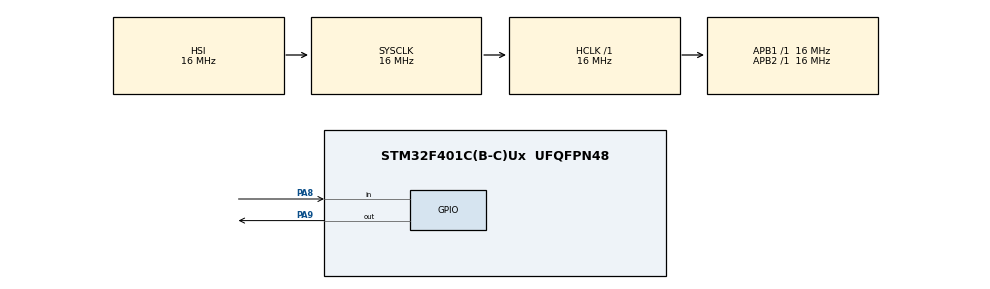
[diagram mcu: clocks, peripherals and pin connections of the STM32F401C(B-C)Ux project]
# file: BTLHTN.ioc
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FREERTOS.BinarySemaphores01=myBinarySem01,Dynamic,NULL
FREERTOS.Tasks01=defaultTask,0,128,StartDefaultTask,Default,NULL,Dynamic,NULL,NULL
Mcu.Family=STM32F4
Mcu.Name=STM32F401C(B-C)Ux
Mcu.Package=UFQFPN48
NVIC.PriorityGroup=NVIC_PRIORITYGROUP_4
NVIC.TIM1_UP_TIM10_IRQn=true\:15\:0\:false\:false\:true\:false\:false\:true
NVIC.TimeBase=TIM1_UP_TIM10_IRQn
NVIC.TimeBaseIP=TIM1
PA8.Signal=GPIO_Input
PA9.Signal=GPIO_Output
ProjectManager.HeapSize=0x200
ProjectManager.StackSize=0x400
ProjectManager.TargetToolchain=MDK-ARM V5.32
RCC.AHBFreq_Value=16000000
RCC.APB1Freq_Value=16000000
RCC.APB1TimFreq_Value=16000000
RCC.APB2Freq_Value=16000000
RCC.APB2TimFreq_Value=16000000
RCC.CortexFreq_Value=16000000
RCC.HCLKFreq_Value=16000000
RCC.HSE_VALUE=25000000
RCC.HSI_VALUE=16000000
RCC.LSE_VALUE=32768
RCC.SYSCLKFreq_VALUE=16000000
RCC.VCOOutputFreq_Value=192000000
TIM2.Period=65535
VP_FREERTOS_VS_CMSIS_V1.Mode=CMSIS_V1
VP_SYS_VS_tim1.Mode=TIM1
VP_TIM2_VS_ClockSourceINT.Mode=Internal
board=custom

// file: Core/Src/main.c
/* USER CODE BEGIN Header */
/**
  ******************************************************************************
  * @file           : main.c
  * @brief          : Main program body
  ******************************************************************************
  * @attention
  *
  * <h2><center>&copy; Copyright (c) 2022 STMicroelectronics.
  * All rights reserved.</center></h2>
  *
  * This software component is licensed by ST under Ultimate Liberty license
  * SLA0044, the "License"; You may not use this file except in compliance with
  * the License. You may obtain a copy of the License at:
  *                             www.st.com/SLA0044
  *
  ******************************************************************************
  */
/* USER CODE END Header */
#include "main.h"
#include "cmsis_os.h"

TIM_HandleTypeDef htim2;

osThreadId defaultTaskHandle;
osSemaphoreId myBinarySem01Handle;

void SystemClock_Config(void);
static void MX_GPIO_Init(void);
static void MX_TIM2_Init(void);
void StartDefaultTask(void const * argument);

int main(void)
{

  /* MCU Configuration--------------------------------------------------------*/

  /* Reset of all peripherals, Initializes the Flash interface and the Systick. */
  HAL_Init();

  /* Configure the system clock */
  SystemClock_Config();

  /* Initialize all configured peripherals */
  MX_GPIO_Init();
  MX_TIM2_Init();

  /* Create the semaphores(s) */
  /* definition and creation of myBinarySem01 */
  osSemaphoreDef(myBinarySem01);
  myBinarySem01Handle = osSemaphoreCreate(osSemaphore(myBinarySem01), 1);

  /* Create the thread(s) */
  /* definition and creation of defaultTask */
  osThreadDef(defaultTask, StartDefaultTask, osPriorityNormal, 0, 128);
  defaultTaskHandle = osThreadCreate(osThread(defaultTask), NULL);

  /* Start scheduler */
  osKernelStart();

  /* We should never get here as control is now taken by the scheduler */
  /* Infinite loop */
  while (1)
  {

  }
}

void SystemClock_Config(void)
{
  RCC_OscInitTypeDef RCC_OscInitStruct = {0};
  RCC_ClkInitTypeDef RCC_ClkInitStruct = {0};

  /** Configure the main internal regulator output voltage
  */
  __HAL_RCC_PWR_CLK_ENABLE();
  __HAL_PWR_VOLTAGESCALING_CONFIG(PWR_REGULATOR_VOLTAGE_SCALE2);
  /** Initializes the RCC Oscillators according to the specified parameters
  * in the RCC_OscInitTypeDef structure.
  */
  RCC_OscInitStruct.OscillatorType = RCC_OSCILLATORTYPE_HSI;
  RCC_OscInitStruct.HSIState = RCC_HSI_ON;
  RCC_OscInitStruct.HSICalibrationValue = RCC_HSICALIBRATION_DEFAULT;
  RCC_OscInitStruct.PLL.PLLState = RCC_PLL_NONE;
  if (HAL_RCC_OscConfig(&RCC_OscInitStruct) != HAL_OK)
  {
    Error_Handler();
  }
  /** Initializes the CPU, AHB and APB buses clocks
  */
  RCC_ClkInitStruct.ClockType = RCC_CLOCKTYPE_HCLK|RCC_CLOCKTYPE_SYSCLK
                              |RCC_CLOCKTYPE_PCLK1|RCC_CLOCKTYPE_PCLK2;
  RCC_ClkInitStruct.SYSCLKSource = RCC_SYSCLKSOURCE_HSI;
  RCC_ClkInitStruct.AHBCLKDivider = RCC_SYSCLK_DIV1;
  RCC_ClkInitStruct.APB1CLKDivider = RCC_HCLK_DIV1;
  RCC_ClkInitStruct.APB2CLKDivider = RCC_HCLK_DIV1;

  if (HAL_RCC_ClockConfig(&RCC_ClkInitStruct, FLASH_LATENCY_0) != HAL_OK)
  {
    Error_Handler();
  }
}

static void MX_TIM2_Init(void)
{

  TIM_ClockConfigTypeDef sClockSourceConfig = {0};
  TIM_MasterConfigTypeDef sMasterConfig = {0};

  htim2.Instance = TIM2;
  htim2.Init.Prescaler = 0;
  htim2.Init.CounterMode = TIM_COUNTERMODE_UP;
  htim2.Init.Period = 65535;
  htim2.Init.ClockDivision = TIM_CLOCKDIVISION_DIV1;
  htim2.Init.AutoReloadPreload = TIM_AUTORELOAD_PRELOAD_DISABLE;
  if (HAL_TIM_Base_Init(&htim2) != HAL_OK)
  {
    Error_Handler();
  }
  sClockSourceConfig.ClockSource = TIM_CLOCKSOURCE_INTERNAL;
  if (HAL_TIM_ConfigClockSource(&htim2, &sClockSourceConfig) != HAL_OK)
  {
    Error_Handler();
  }
  sMasterConfig.MasterOutputTrigger = TIM_TRGO_RESET;
  sMasterConfig.MasterSlaveMode = TIM_MASTERSLAVEMODE_DISABLE;
  if (HAL_TIMEx_MasterConfigSynchronization(&htim2, &sMasterConfig) != HAL_OK)
  {
    Error_Handler();
  }

}

static void MX_GPIO_Init(void)
{
  GPIO_InitTypeDef GPIO_InitStruct = {0};

  /* GPIO Ports Clock Enable */
  __HAL_RCC_GPIOA_CLK_ENABLE();

  /*Configure GPIO pin Output Level */
  HAL_GPIO_WritePin(GPIOA, GPIO_PIN_9, GPIO_PIN_RESET);

  /*Configure GPIO pin : PA8 */
  GPIO_InitStruct.Pin = GPIO_PIN_8;
  GPIO_InitStruct.Mode = GPIO_MODE_INPUT;
  GPIO_InitStruct.Pull = GPIO_NOPULL;
  HAL_GPIO_Init(GPIOA, &GPIO_InitStruct);

  /*Configure GPIO pin : PA9 */
  GPIO_InitStruct.Pin = GPIO_PIN_9;
  GPIO_InitStruct.Mode = GPIO_MODE_OUTPUT_PP;
  GPIO_InitStruct.Pull = GPIO_NOPULL;
  GPIO_InitStruct.Speed = GPIO_SPEED_FREQ_LOW;
  HAL_GPIO_Init(GPIOA, &GPIO_InitStruct);

}

/* USER CODE BEGIN 4 */
static void sw_uart_test_thread(void *arg)
{
    uint8_t c;

    sw_uart_init(PB_4, PB_5, 9600);

    while(1) {
        sw_uart_getc(&c);
        sw_uart_putc(c);
    }
}

/* USER CODE END 4 */

void StartDefaultTask(void const * argument)
{
  for(;;)
  {
    osDelay(1);
  }
}

void HAL_TIM_PeriodElapsedCallback(TIM_HandleTypeDef *htim)
{
  if (htim->Instance == TIM1) {
    HAL_IncTick();
  }
}

void Error_Handler(void)
{
  __disable_irq();
  while (1)
  {
  }
}

/************************ (C) COPYRIGHT STMicroelectronics *****END OF FILE****/
